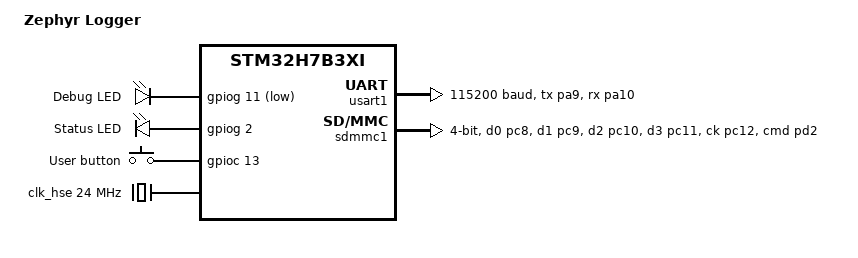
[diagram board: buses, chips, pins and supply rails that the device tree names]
/*
 * Minimal board definition for the Zephyr Logger custom board.
 *
 * SPDX-License-Identifier: Apache-2.0
 */

/dts-v1/;
#include <st/h7/stm32h7b3Xi.dtsi>
#include <st/h7/stm32h7b3lihxq-pinctrl.dtsi>
#include <zephyr/dt-bindings/input/input-event-codes.h>

/ {
	model = "Zephyr Logger";
	compatible = "custom,zephyr-logger";

	chosen {
		zephyr,console = &usart1;
		zephyr,shell-uart = &usart1;
		zephyr,sram = &sram0;
		zephyr,flash = &flash0;
	};

	leds {
		compatible = "gpio-leds";

		debug_led: led_0 {
			gpios = <&gpiog 11 GPIO_ACTIVE_LOW>;
			label = "Debug LED";
		};

		status_led: led_1 {
			gpios = <&gpiog 2 GPIO_ACTIVE_HIGH>;
			label = "Status LED";
		};
	};

	buttons {
		compatible = "gpio-keys";

		user_button: button_0 {
			gpios = <&gpioc 13 GPIO_ACTIVE_HIGH>;
			label = "User button";
			zephyr,code = <INPUT_KEY_0>;
		};
	};

	aliases {
		led0 = &debug_led;
		led1 = &status_led;
		debug-led = &debug_led;
		status-led = &status_led;
		sw0 = &user_button;
	};
};

&clk_hse {
	clock-frequency = <DT_FREQ_M(24)>;
	status = "okay";
};

&pll {
	div-m = <12>;
	mul-n = <280>;
	div-p = <2>;
	div-q = <7>;
	div-r = <2>;
	clocks = <&clk_hse>;
	status = "okay";
};

/* Dedicated 48 MHz kernel clock for SDMMC1: 24 MHz / 12 * 192 / 8. */
&pll2 {
	div-m = <12>;
	mul-n = <192>;
	div-p = <8>;
	div-q = <8>;
	div-r = <8>;
	clocks = <&clk_hse>;
	status = "okay";
};

&rcc {
	clocks = <&pll>;
	clock-frequency = <DT_FREQ_M(280)>;
	d1cpre = <1>;
	hpre = <1>;
	d1ppre = <2>;
	d2ppre1 = <2>;
	d2ppre2 = <2>;
	d3ppre = <2>;
};

&pwr {
	power-supply = "smps-direct";
};

&usart1 {
	pinctrl-0 = <&usart1_tx_pa9 &usart1_rx_pa10>;
	pinctrl-names = "default";
	current-speed = <115200>;
	status = "okay";
};

/*
 * microSD connector, matching the STM32H7B3I-DK wiring.
 * The card uses SDMMC1 in 4-bit mode; PI8 is low while a card is inserted.
 */
&sdmmc1 {
	clocks = <&rcc STM32_CLOCK(AHB3, 16)>,
		 <&rcc STM32_SRC_PLL2_R SDMMC_SEL(1)>;
	pinctrl-0 = <&sdmmc1_d0_pc8 &sdmmc1_d1_pc9
		     &sdmmc1_d2_pc10 &sdmmc1_d3_pc11
		     &sdmmc1_ck_pc12 &sdmmc1_cmd_pd2>;
	pinctrl-names = "default";
	cd-gpios = <&gpioi 8 (GPIO_ACTIVE_LOW | GPIO_PULL_UP)>;
	disk-name = "SD";
	bus-width = <4>;
	status = "okay";
};
